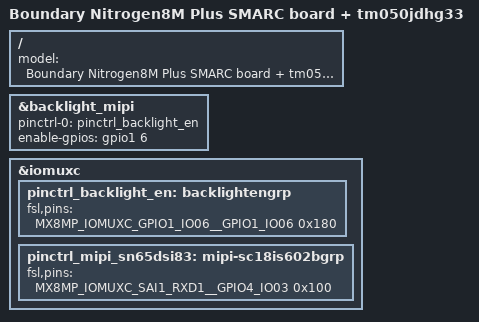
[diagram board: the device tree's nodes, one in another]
// SPDX-License-Identifier: (GPL-2.0+ OR MIT)
/*
 * Copyright 2026 Ezurio LLC
 */

/dts-v1/;

#include "imx8mp-nitrogen_smarc.dts"

/ {
	model = "Boundary Nitrogen8M Plus SMARC board + tm050jdhg33";
};

&backlight_mipi {
	pinctrl-names = "default";
	pinctrl-0 = <&pinctrl_backlight_en>;
	enable-gpios = <&gpio1 6 GPIO_ACTIVE_HIGH>;
};


&iomuxc {
	pinctrl_backlight_en: backlightengrp {
	      fsl,pins = <
		      MX8MP_IOMUXC_GPIO1_IO06__GPIO1_IO06     0x180
	      >;
	};

	/delete-node/ pinctrl_mipi_sn65dsi83;

	pinctrl_mipi_sn65dsi83: mipi-sc18is602bgrp {
		fsl,pins = <
			MX8MP_IOMUXC_SAI1_RXD1__GPIO4_IO03      0x100
		>;
	};
};
